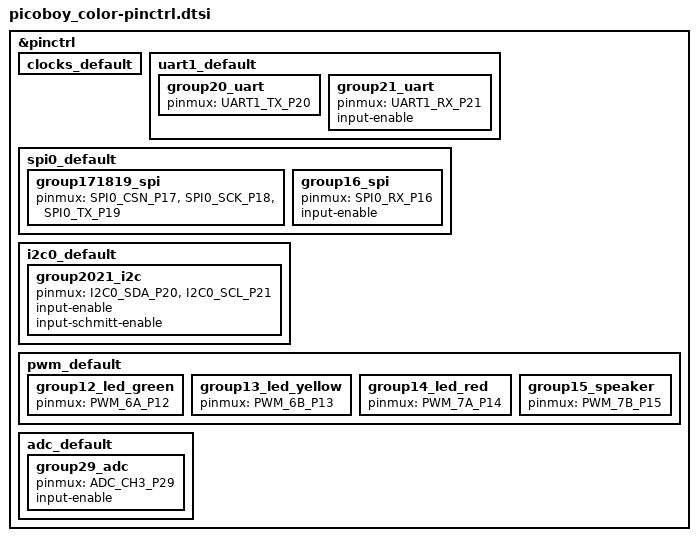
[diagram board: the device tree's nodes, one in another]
/*
 * SPDX-FileCopyrightText: Copyright (c) 2023-2026 TiaC Systems
 * SPDX-License-Identifier: Apache-2.0
 */

#include <zephyr/dt-bindings/pinctrl/rpi-pico-rp2040-pinctrl.h>

&pinctrl {
	clocks_default: clocks_default {
		/* no external clocks */
	};

	uart1_default: uart1_default {			/* solder pads */
		group20_uart {				/* as UART i/f */
			pinmux = <UART1_TX_P20>;
		};
		group21_uart {
			pinmux = <UART1_RX_P21>;
			input-enable;
		};
	};

	spi0_default: spi0_default {
		group171819_spi {
			pinmux = <SPI0_CSN_P17>,	/* not wired */
				 <SPI0_SCK_P18>,	/* LCD display */
				 <SPI0_TX_P19>;		/* ST7789V (240x280) */
		};
		group16_spi {
			pinmux = <SPI0_RX_P16>;		/* not wired */
			input-enable;
		};
	};

	i2c0_default: i2c0_default {			/* solder pads */
		group2021_i2c {				/* as I2C bus */
			pinmux = <I2C0_SDA_P20>,
				 <I2C0_SCL_P21>;
			input-enable;
			input-schmitt-enable;
		};
	};

	pwm_default: pwm_default {
		group12_led_green {
			pinmux = <PWM_6A_P12>;		/* Green LED */
		};
		group13_led_yellow {
			pinmux = <PWM_6B_P13>;		/* Yellow LED */
		};
		group14_led_red {
			pinmux = <PWM_7A_P14>;		/* Red LED */
		};
		group15_speaker {
			pinmux = <PWM_7B_P15>;		/* Speaker */
		};
	};

	adc_default: adc_default {
		group29_adc {
			pinmux = <ADC_CH3_P29>;
			input-enable;
		};
	};
};
